# STM32L471xx register map
File version: 1.0
Registers are 32-bit, read-write, reset 0x0 unless marked. A register's access mark holds for its fields unless they carry their own. Offsets are from the block's base; [hi:lo] are bit positions; {n}, {i} and the like mark numbered series.

## SPI2 — Serial Peripheral Interface
Base 0x40003800
Same registers: SPI3 0x40003C00, SPI1 0x40013000
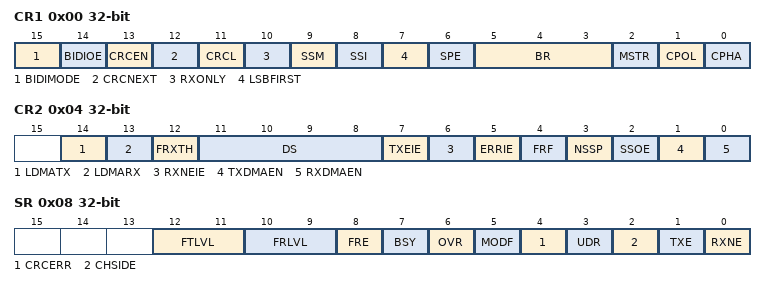
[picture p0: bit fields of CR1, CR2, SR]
0x00 CR1 — SPI Control register 1
  [15] BIDIMODE — Bidirectional data mode enable
  [14] BIDIOE — Output enable in bidirectional mode
  [13] CRCEN — Hardware CRC calculation enable
  [12] CRCNEXT — Transmit CRC next
  [11] CRCL — CRC Length
    0=CRC_8BIT (8-bit CRC length); 1=CRC_16BIT (16-bit CRC length)
  [10] RXONLY — Receive only
  [9] SSM — Software slave management
  [8] SSI — Internal slave select
  [7] LSBFIRST — Frame Format
    1=LSB_FIRST (Data is transmitted/received with the LSB first); 0=MSB_FIRST (Data is transmitted/received with the MSB first)
  [6] SPE — SPI Enable
  [5:3] BR — BR[2:0] bits (Baud Rate Control)
    0=DIV2 (BaudRate control equal to fPCLK/2); 1=DIV4 (BaudRate control equal to fPCLK/4); 2=DIV8 (BaudRate control equal to fPCLK/8); 3=DIV16 (BaudRate control equal to fPCLK/16); 4=DIV32 (BaudRate control equal to fPCLK/32); 5=DIV64 (BaudRate control equal to fPCLK/64); 6=DIV128 (BaudRate control equal to fPCLK/128); 7=DIV256 (BaudRate control equal to fPCLK/256)
  [2] MSTR — Master Selection
  [1] CPOL — Clock Polarity
    0=LOW (Clock to 0 when idle); 1=HIGH (Clock to 1 when idle)
  [0] CPHA — Clock Phase
    0=PHASE_1EDGE (First clock transition is the first data capture edge); 1=PHASE_2EDGE (Second clock transition is the first data capture edge)
0x04 CR2 — SPI Control register 2
  [14] LDMATX — Last DMA transfer for transmission
  [13] LDMARX — Last DMA transfer for reception
  [12] FRXTH — FIFO reception Threshold
    0=HALF (RXNE event is generated if FIFO level is greater than or equal to 1/2 (16-bit)); 1=QUARTER (RXNE event is generated if FIFO level is greater than or equal to 1/4 (8-bit))
  [11:8] DS — DS[3:0] Data Size
    {v}=DATAWIDTH_{v+1}BIT (Data length for SPI transfer: {v+1} bits) (v=3..15)
  [7] TXEIE — Tx buffer Empty Interrupt Enable
  [6] RXNEIE — RX buffer Not Empty Interrupt Enable
  [5] ERRIE — Error Interrupt Enable
  [4] FRF — Frame Format Enable
    0=MOTOROLA (Motorola mode. Used as default value); 1=TI (TI mode)
  [3] NSSP — NSS pulse management Enable
  [2] SSOE — SS Output Enable
  [1] TXDMAEN — Tx Buffer DMA Enable
  [0] RXDMAEN — Rx Buffer DMA Enable
0x08 SR — SPI Status register
  [12:11] FTLVL — FIFO Transmission Level
    0=EMPTY (FIFO transmission empty); 1=QUARTER_FULL (FIFO transmission 1/4); 2=HALF_FULL (FIFO transmission 1/2); 3=FULL (FIFO transmission full)
  [10:9] FRLVL — FIFO Reception Level
    0=EMPTY (FIFO reception empty); 1=QUARTER_FULL (FIFO reception 1/4); 2=HALF_FULL (FIFO reception 1/2); 3=FULL (FIFO reception full)
  [8] FRE — TI frame format error
  [7] BSY — Busy flag
  [6] OVR — Overrun flag
  [5] MODF — Mode fault
  [4] CRCERR — CRC Error flag
  [3] UDR — Underrun flag
  [2] CHSIDE — Channel side
  [1] TXE — Transmit buffer Empty
  [0] RXNE — Receive buffer Not Empty
0x0C DR — SPI data register
  [15:0] DR — Data Register
0x10 CRCPR — SPI CRC polynomial register
  [15:0] CRCPOLY — CRC polynomial register
0x14 RXCRCR — SPI Rx CRC register
  [15:0] RXCRC
0x18 TXCRCR — SPI Tx CRC register
  [15:0] TXCRC

## PWR — Power Control
Base 0x40007000
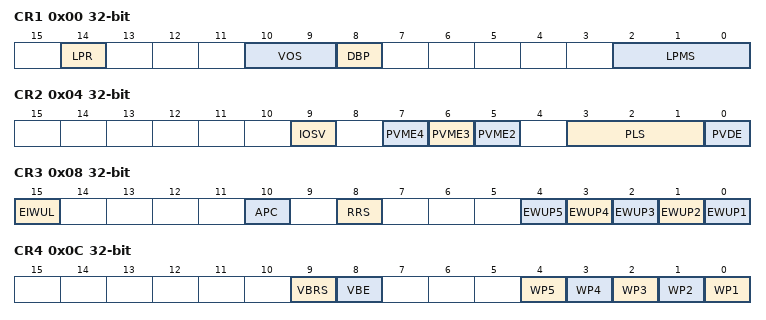
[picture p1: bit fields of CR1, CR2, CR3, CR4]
0x00 CR1 — PWR power control register 1
  [14] LPR — Regulator low-power mode
  [10:9] VOS — VOS[1:0] bits (Regulator voltage scaling output selection)
    1=SCALE1; 2=SCALE2
  [8] DBP — Disable Back-up domain Protection
  [2:0] LPMS — Low-power mode selection field
    0=STOP0; 1=STOP1; 2=STOP2; 3=STANDBY; 4=SHUTDOWN
0x04 CR2 — PWR power control register 2
  [9] IOSV — VDD IO2 independent I/Os Supply Valid
  [7] PVME4 — PVM 4 Enable
  [6] PVME3 — PVM 3 Enable
  [5] PVME2 — PVM 2 Enable
  [3:1] PLS — PVD level selection
    {v}=PVDLEVEL_{v} (v=0..7)
  [0] PVDE — Power Voltage Detector Enable
0x08 CR3 — PWR power control register 3
  [15] EIWUL — Enable Internal Wake-up line
  [10] APC — Apply pull-up and pull-down configuration
  [8] RRS — SRAM2 Retention in Stand-by mode
    0=NO_SRAM2_RETENTION; 1=FULL_SRAM2_RETENTION
  [n-1] EWUP{n} (n=1..5) — Enable Wake-Up Pin {n}
0x0C CR4 — PWR power control register 4
  [9] VBRS — VBAT Battery charging Resistor Selection
    0=CHARG_RESISTOR_5K; 1=CHARGRESISTOR_1_5K
  [8] VBE — VBAT Battery charging Enable
  [n-1] WP{n} (n=1..5) — Wake-Up Pin {n} polarity
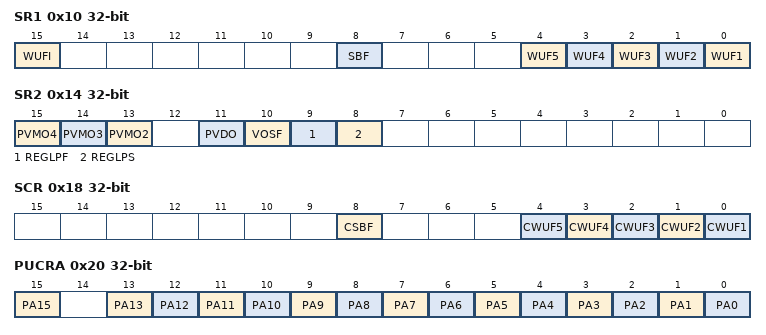
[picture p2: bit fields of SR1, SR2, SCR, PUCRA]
0x10 SR1 — PWR power status register 1
  [15] WUFI — Wake-Up Flag Internal
  [8] SBF — Stand-By Flag
  [n-1] WUF{n} (n=1..5) — Wake-up Flag {n}
0x14 SR2 — PWR power status register 2
  [15] PVMO4 — Peripheral Voltage Monitoring Output 4
  [14] PVMO3 — Peripheral Voltage Monitoring Output 3
  [13] PVMO2 — Peripheral Voltage Monitoring Output 2
  [11] PVDO — Power Voltage Detector Output
  [10] VOSF — Voltage Scaling Flag
  [9] REGLPF — Low-power Regulator Flag
  [8] REGLPS — Low-power Regulator Started
0x18 SCR — PWR power status reset register
  [8] CSBF — Clear Stand-By Flag
  [n-1] CWUF{n} (n=1..5) — Clear Wake-up Flag {n}
0x20 PUCRA — Pull_up control register of portA
  [15] PA15 — Port PA15 Pull-Up set
  [n] PA{n} (n=0..13) — Port PA{n} Pull-Up set
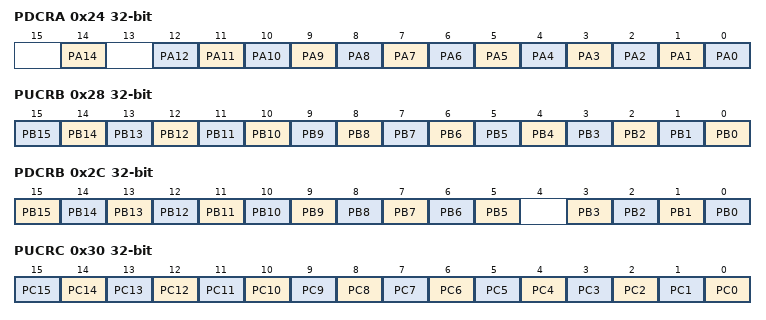
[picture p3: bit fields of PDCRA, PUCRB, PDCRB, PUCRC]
0x24 PDCRA — Pull_Down control register of portA
  [14] PA14 — Port PA14 Pull-Down set
  [n] PA{n} (n=0..12) — Port PA{n} Pull-Down set
0x28 PUCRB — Pull_up control register of portB
  [n] PB{n} (n=0..15) — Port PB{n} Pull-Up set
0x2C PDCRB — Pull_Down control register of portB
  [n] PB{n} (n=5..15) — Port PB{n} Pull-Down set
  [n] PB{n} (n=0..3) — Port PB{n} Pull-Down set
0x30 PUCRC — Pull_up control register of portC
  [n] PC{n} (n=0..15) — Port PC{n} Pull-Up set
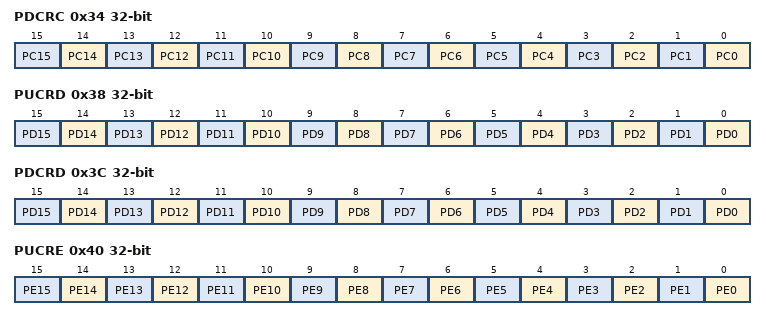
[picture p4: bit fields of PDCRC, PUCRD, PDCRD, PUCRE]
0x34 PDCRC — Pull_Down control register of portC
  [n] PC{n} (n=0..15) — Port PC{n} Pull-Down set
0x38 PUCRD — Pull_up control register of portD
  [n] PD{n} (n=0..15) — Port PD{n} Pull-Up set
0x3C PDCRD — Pull_Down control register of portD
  [n] PD{n} (n=0..15) — Port PD{n} Pull-Down set
0x40 PUCRE — Pull_up control register of portE
  [n] PE{n} (n=0..15) — Port PE{n} Pull-Up set
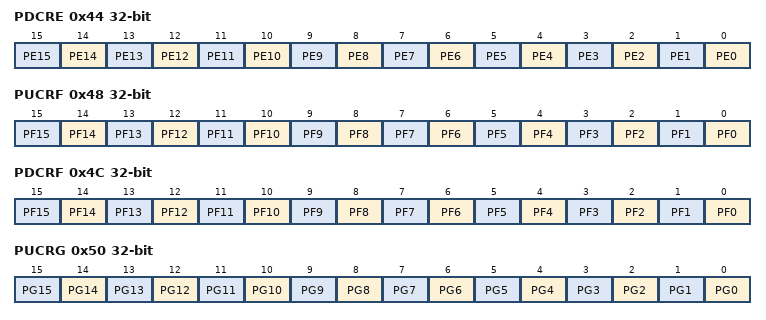
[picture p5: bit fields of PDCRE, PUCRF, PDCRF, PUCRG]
0x44 PDCRE — Pull_Down control register of portE
  [n] PE{n} (n=0..15) — Port PE{n} Pull-Down set
0x48 PUCRF — Pull_up control register of portF
  [n] PF{n} (n=0..15) — Port PF{n} Pull-Up set
0x4C PDCRF — Pull_Down control register of portF
  [n] PF{n} (n=0..15) — Port PF{n} Pull-Down set
0x50 PUCRG — Pull_up control register of portG
  [n] PG{n} (n=0..15) — Port PG{n} Pull-Up set
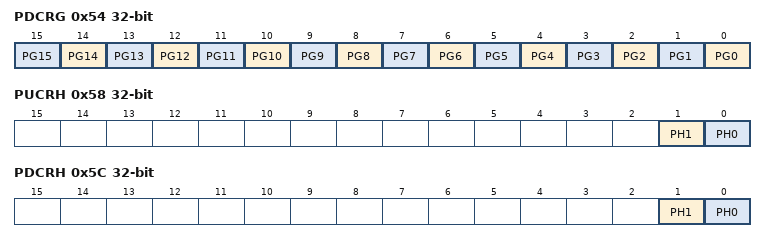
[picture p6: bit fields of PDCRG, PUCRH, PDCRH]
0x54 PDCRG — Pull_Down control register of portG
  [n] PG{n} (n=0..15) — Port PG{n} Pull-Down set
0x58 PUCRH — Pull_up control register of portH
  [1] PH1 — Port PH1 Pull-Up set
  [0] PH0 — Port PH0 Pull-Up set
0x5C PDCRH — Pull_Down control register of portH
  [1] PH1 — Port PH1 Pull-Down set
  [0] PH0 — Port PH0 Pull-Down set
